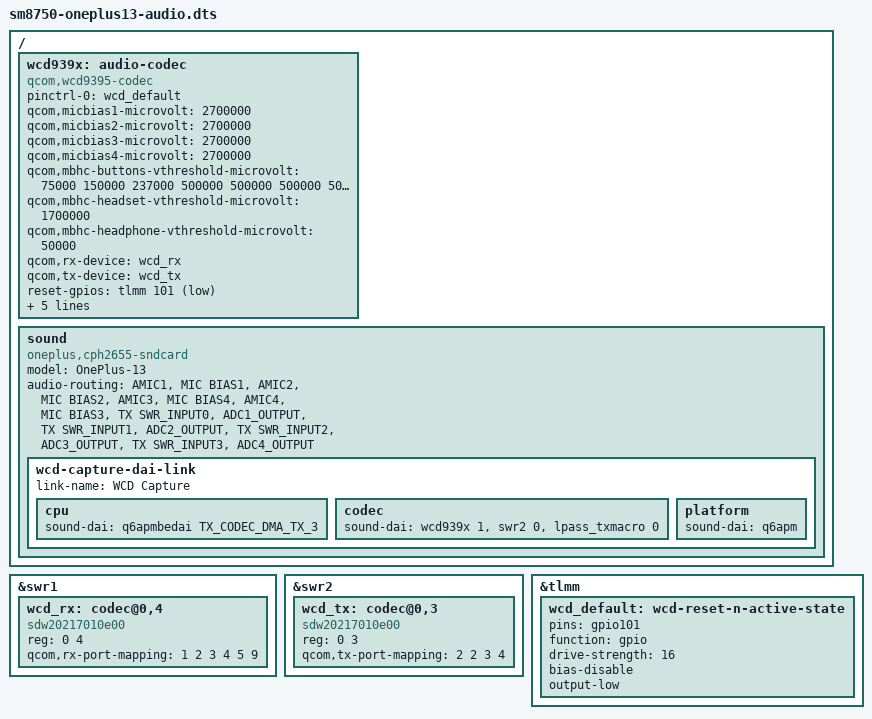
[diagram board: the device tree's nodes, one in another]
// SPDX-License-Identifier: BSD-3-Clause
/* Audio, microphones. WCD9395 over SoundWire, wired as on the SM8750 MTP
 * (reset TLMM101, L15B/BOB1/L2I, RX unique ID 4, TX unique ID 3; checked
 * against the saved CPH2655 stock tree). The graphs come from the board's
 * AudioReach topology (OnePlus-13-tplg.bin). Speakers: see speakers.dts.
 */
#include <dt-bindings/sound/qcom,q6dsp-lpass-ports.h>
#include "sm8750-oneplus13-bluetooth.dts"

/ {
	wcd939x: audio-codec {
		compatible = "qcom,wcd9395-codec", "qcom,wcd9390-codec";
		pinctrl-0 = <&wcd_default>;
		pinctrl-names = "default";

		/* Stock qcom,cdc-micbias*-mv = 2700 */
		qcom,micbias1-microvolt = <2700000>;
		qcom,micbias2-microvolt = <2700000>;
		qcom,micbias3-microvolt = <2700000>;
		qcom,micbias4-microvolt = <2700000>;
		qcom,mbhc-buttons-vthreshold-microvolt = <75000 150000 237000 500000 500000 500000 500000 500000>;
		qcom,mbhc-headset-vthreshold-microvolt = <1700000>;
		qcom,mbhc-headphone-vthreshold-microvolt = <50000>;
		qcom,rx-device = <&wcd_rx>;
		qcom,tx-device = <&wcd_tx>;

		reset-gpios = <&tlmm 101 GPIO_ACTIVE_LOW>;

		vdd-buck-supply = <&vreg_l15b_1p8>;
		vdd-rxtx-supply = <&vreg_l15b_1p8>;
		vdd-io-supply = <&vreg_l15b_1p8>;
		vdd-mic-bias-supply = <&vreg_bob1>;
		vdd-px-supply = <&vreg_l2i_1p2>;

		#sound-dai-cells = <1>;
	};

	sound: sound {
		compatible = "oneplus,cph2655-sndcard";
		model = "OnePlus-13";

		/* Stock pairs: AMIC1/BIAS1, AMIC2/BIAS2, AMIC3/BIAS4, AMIC4/BIAS3 */
		audio-routing = "AMIC1", "MIC BIAS1",
				"AMIC2", "MIC BIAS2",
				"AMIC3", "MIC BIAS4",
				"AMIC4", "MIC BIAS3",
				"TX SWR_INPUT0", "ADC1_OUTPUT",
				"TX SWR_INPUT1", "ADC2_OUTPUT",
				"TX SWR_INPUT2", "ADC3_OUTPUT",
				"TX SWR_INPUT3", "ADC4_OUTPUT";

		wcd-capture-dai-link {
			link-name = "WCD Capture";

			cpu {
				sound-dai = <&q6apmbedai TX_CODEC_DMA_TX_3>;
			};

			codec {
				sound-dai = <&wcd939x 1>, <&swr2 0>, <&lpass_txmacro 0>;
			};

			platform {
				sound-dai = <&q6apm>;
			};
		};
	};
};

&swr1 {
	status = "okay";

	/* WCD9395 RX: the codec binds only with both SoundWire slaves present */
	wcd_rx: codec@0,4 {
		compatible = "sdw20217010e00";
		reg = <0 4>;
		qcom,rx-port-mapping = <1 2 3 4 5 9>;
	};
};

&swr2 {
	status = "okay";

	/* WCD9395 TX */
	wcd_tx: codec@0,3 {
		compatible = "sdw20217010e00";
		reg = <0 3>;
		qcom,tx-port-mapping = <2 2 3 4>;
	};
};

&tlmm {
	wcd_default: wcd-reset-n-active-state {
		pins = "gpio101";
		function = "gpio";
		drive-strength = <16>;
		bias-disable;
		output-low;
	};
};
